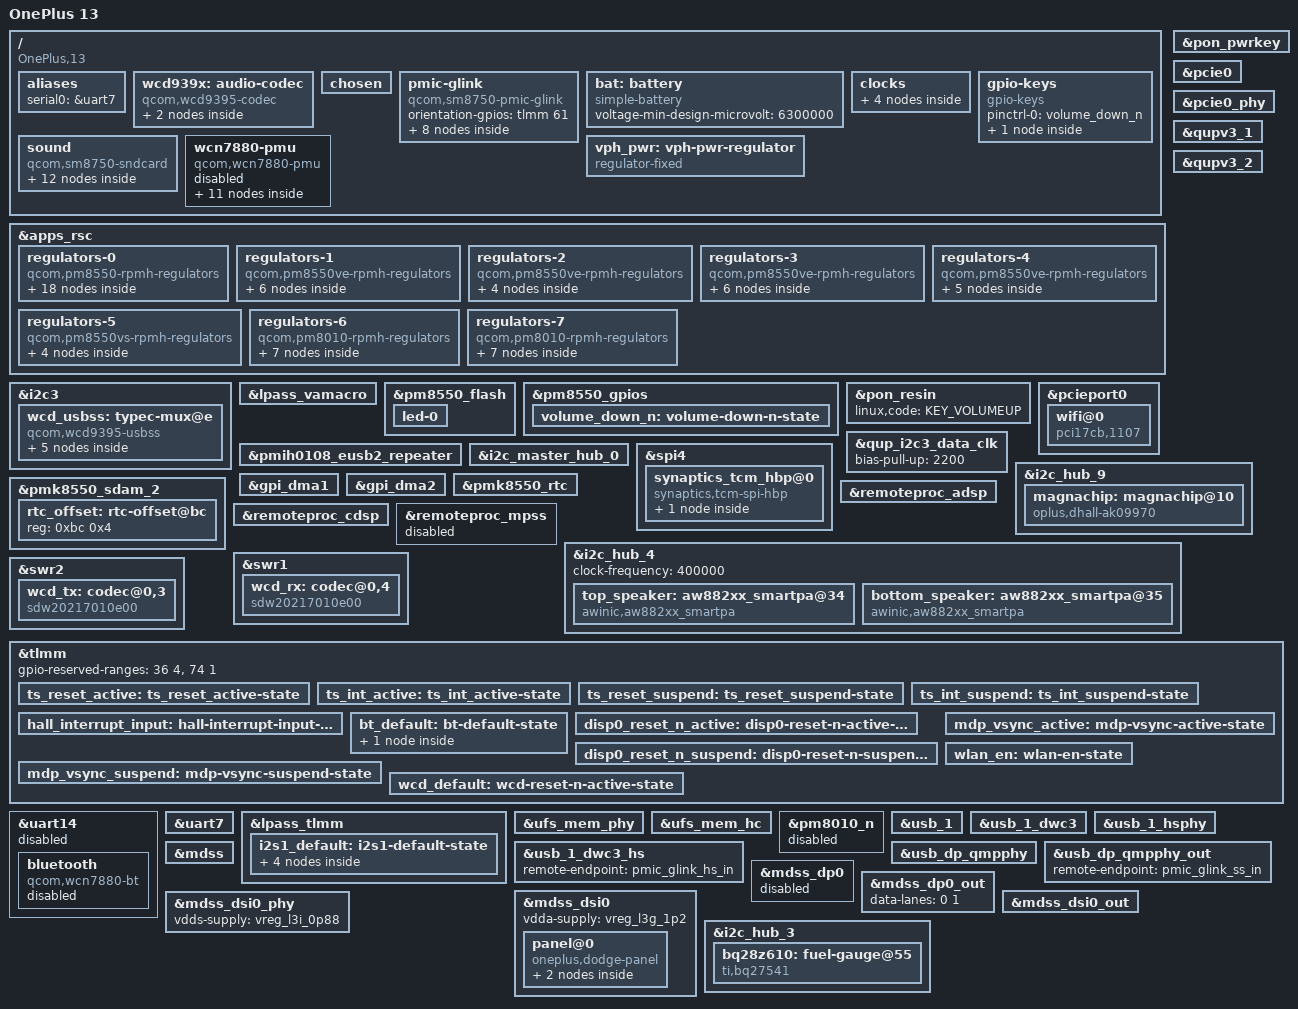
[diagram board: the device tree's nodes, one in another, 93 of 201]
// SPDX-License-Identifier: BSD-3-Clause
/*
 * Copyright (c) 2025 index986. All rights reserved.
 */

/dts-v1/;

#include <dt-bindings/gpio/gpio.h
#include <dt-bindings/leds/common.h>
#include <dt-bindings/regulator/qcom,rpmh-regulator.h>
#include "sm8750.dtsi"
#include "pm8010.dtsi"
#include "pm8550.dtsi"
#define PMK8550VE_SID 8
#include "pm8550ve.dtsi"
#include "pmd8028.dtsi"
#include "pmih0108.dtsi"
#include "pmk8550.dtsi"
#include "pmr735d_a.dtsi"
#include "sm8750-pmics.dtsi"

/ {
	model = "OnePlus 13";
	compatible = "OnePlus,13", "qcom,sm8750";
	chassis-type = "handset";

	aliases {
		serial0 = &uart7;
	};

	wcd939x: audio-codec {
		compatible = "qcom,wcd9395-codec", "qcom,wcd9390-codec";

		pinctrl-0 = <&wcd_default>;
		pinctrl-names = "default";

		qcom,micbias1-microvolt = <1800000>;
		qcom,micbias2-microvolt = <1800000>;
		qcom,micbias3-microvolt = <1800000>;
		qcom,micbias4-microvolt = <1800000>;
		qcom,mbhc-buttons-vthreshold-microvolt = <75000 150000 237000 500000 500000 500000 500000 500000>;
		qcom,mbhc-headset-vthreshold-microvolt = <1700000>;
		qcom,mbhc-headphone-vthreshold-microvolt = <50000>;
		qcom,rx-device = <&wcd_rx>;
		qcom,tx-device = <&wcd_tx>;

		reset-gpios = <&tlmm 101 GPIO_ACTIVE_LOW>;

		vdd-buck-supply = <&vreg_l15b_1p8>;
		vdd-rxtx-supply = <&vreg_l15b_1p8>;
		vdd-io-supply = <&vreg_l15b_1p8>;
		vdd-mic-bias-supply = <&vreg_bob1>;
		vdd-px-supply = <&vreg_l2i_1p2>;

		#sound-dai-cells = <1>;

		mode-switch;
		orientation-switch;

		port {
			wcd_codec_headset_in: endpoint {
				remote-endpoint = <&wcd_usbss_headset_out>;
			};
		};
	};

	chosen {
		#address-cells = <2>;
		#size-cells = <2>;
		ranges;
	};
	
	pmic-glink {
		compatible = "qcom,sm8750-pmic-glink",
			     "qcom,sm8550-pmic-glink",
			     "qcom,pmic-glink";
		#address-cells = <1>;
		#size-cells = <0>;
		orientation-gpios = <&tlmm 61 GPIO_ACTIVE_HIGH>;

		connector@0 {
			compatible = "usb-c-connector";
			reg = <0>;

			power-role = "dual";
			data-role = "dual";

			ports {
				#address-cells = <1>;
				#size-cells = <0>;

				port@0 {
					reg = <0>;
					pmic_glink_hs_in: endpoint {
						remote-endpoint = <&usb_1_dwc3_hs>;
					};
				};

				port@1 {
					reg = <1>;
					pmic_glink_ss_in: endpoint {
						remote-endpoint = <&usb_dp_qmpphy_out>;
					};
				};

				port@2 {
					reg = <2>;

					pmic_glink_sbu: endpoint {
						remote-endpoint = <&wcd_usbss_sbu_mux>;
					};
				};
			};
		};
	};

	bat: battery {
		compatible = "simple-battery";
		voltage-min-design-microvolt = <6300000>;
	};

	clocks {
		xo_board: xo-board {
			compatible = "fixed-clock";
			clock-frequency = <76800000>;
			#clock-cells = <0>;
		};

		sleep_clk: sleep-clk {
			compatible = "fixed-clock";
			clock-frequency = <32000>;
			#clock-cells = <0>;
		};

		bi_tcxo_div2: bi-tcxo-div2-clk {
			compatible = "fixed-factor-clock";
			#clock-cells = <0>;

			clocks = <&rpmhcc RPMH_CXO_CLK>;
			clock-mult = <1>;
			clock-div = <2>;
		};

		bi_tcxo_ao_div2: bi-tcxo-ao-div2-clk {
			compatible = "fixed-factor-clock";
			#clock-cells = <0>;

			clocks = <&rpmhcc RPMH_CXO_CLK_A>;
			clock-mult = <1>;
			clock-div = <2>;
		};
	};

	gpio-keys {
		compatible = "gpio-keys";

		pinctrl-0 = <&volume_down_n>;
		pinctrl-names = "default";

		key-volume-down {
			label = "Volume Down";
			linux,code = <KEY_VOLUMEDOWN>;
			gpios = <&pm8550_gpios 6 GPIO_ACTIVE_LOW>;
			debounce-interval = <15>;
			linux,can-disable;
			wakeup-source;
		};
	};

	sound {
		compatible = "qcom,sm8750-sndcard", "qcom,sm8450-sndcard";
		pinctrl-0 = <&i2s1_default>;
		pinctrl-names = "default";

		clocks = <&q6prmcc LPASS_CLK_ID_SEC_MI2S_IBIT LPASS_CLK_ATTRIBUTE_COUPLE_NO>;

		model = "astonsnd";
		audio-routing = "IN1_HPHL", "HPHL_OUT",
				"IN2_HPHR", "HPHR_OUT",
				"AMIC1", "MIC BIAS1",
				"AMIC2", "MIC BIAS2",
				"AMIC3", "MIC BIAS3",
				"AMIC4", "MIC BIAS4",
				"AMIC5", "MIC BIAS3",
				"TX SWR_INPUT0", "ADC1_OUTPUT",
				"TX SWR_INPUT1", "ADC2_OUTPUT",
				"TX SWR_INPUT0", "ADC3_OUTPUT",
				"TX SWR_INPUT1", "ADC4_OUTPUT";

		wcd-playback-dai-link {
			link-name = "WCD Playback";
			cpu {
				sound-dai = <&q6apmbedai RX_CODEC_DMA_RX_0>;
			};
			codec {
				sound-dai = <&wcd939x 0>, <&swr1 0>, <&lpass_rxmacro 0>;
			};
			platform {
				sound-dai = <&q6apm>;
			};
		};

		wcd-capture-dai-link {
			link-name = "WCD Capture";
			cpu {
				sound-dai = <&q6apmbedai TX_CODEC_DMA_TX_3>;
			};
			codec {
				sound-dai = <&wcd939x 1>, <&swr2 0>, <&lpass_txmacro 0>;
			};
			platform {
				sound-dai = <&q6apm>;
			};
		};

		secondary-i2s-dai-link {
			link-name = "Secondary MI2S Playback";

			cpu {
				sound-dai = <&q6apmbedai SECONDARY_MI2S_RX>;
			};

			platform {
				sound-dai = <&q6apm>;
			};

			codec {
				sound-dai = <&top_speaker>, <&bottom_speaker>;
			};
		};

	};
	
	vph_pwr: vph-pwr-regulator {
		compatible = "regulator-fixed";

		regulator-name = "vph_pwr";
		regulator-min-microvolt = <3700000>;
		regulator-max-microvolt = <3700000>;

		regulator-always-on;
		regulator-boot-on;
	};

	wcn7880-pmu { // No compatible drivers
		compatible = "qcom,wcn7880-pmu";

		pinctrl-names = "default";
		pinctrl-0 = <&wlan_en>, <&bt_default>;

		wlan-enable-gpios = <&tlmm 16 GPIO_ACTIVE_HIGH>;
		bt-enable-gpios = <&pm8550ve_f_gpios 3 GPIO_ACTIVE_HIGH>;

		vdd-supply = <&vreg_s5f_0p85>;
		vddio-supply = <&vreg_l3f_1p8>;
		vddio1p2-supply = <&vreg_l2f_1p2>;
		vddaon-supply = <&vreg_s4d_0p85>;
		vdddig-supply = <&vreg_s1d_0p97>;
		vddrfa1p2-supply = <&vreg_s7i_1p2>;
		vddrfa1p8-supply = <&vreg_s3g_1p8>;
			
		status = "disabled";

		clocks = <&rpmhcc RPMH_RF_CLK1>;

		regulators {
			vreg_pmu_rfa_cmn: ldo0 {
				regulator-name = "vreg_pmu_rfa_cmn";
			};

			vreg_pmu_aon_0p59: ldo1 {
				regulator-name = "vreg_pmu_aon_0p59";
			};

			vreg_pmu_wlcx_0p8: ldo2 {
				regulator-name = "vreg_pmu_wlcx_0p8";
			};

			vreg_pmu_wlmx_0p85: ldo3 {
				regulator-name = "vreg_pmu_wlmx_0p85";
			};

			vreg_pmu_btcmx_0p85: ldo4 {
				regulator-name = "vreg_pmu_btcmx_0p85";
			};

			vreg_pmu_rfa_0p8: ldo5 {
				regulator-name = "vreg_pmu_rfa_0p8";
			};

			vreg_pmu_rfa_1p2: ldo6 {
				regulator-name = "vreg_pmu_rfa_1p2";
			};

			vreg_pmu_rfa_1p8: ldo7 {
				regulator-name = "vreg_pmu_rfa_1p8";
			};

			vreg_pmu_pcie_0p9: ldo8 {
				regulator-name = "vreg_pmu_pcie_0p9";
			};

			vreg_pmu_pcie_1p8: ldo9 {
				regulator-name = "vreg_pmu_pcie_1p8";
			};
		};
	};
};

&apps_rsc {
	regulators-0 {
		compatible = "qcom,pm8550-rpmh-regulators";

		vdd-bob1-supply = <&vph_pwr>;
		vdd-bob2-supply = <&vph_pwr>;
		vdd-l1-l4-l10-supply = <&vreg_s3g_1p8>;
		vdd-l2-l13-l14-supply = <&vreg_bob1>;
		vdd-l3-supply = <&vreg_s7i_1p2>;
		vdd-l5-l16-supply = <&vreg_bob1>;
		vdd-l6-l7-supply = <&vreg_bob1>;
		vdd-l8-l9-supply = <&vreg_bob1>;
		vdd-l11-supply = <&vreg_s7i_1p2>;
		vdd-l12-supply = <&vreg_s3g_1p8>;
		vdd-l15-supply = <&vreg_s3g_1p8>;
		vdd-l17-supply = <&vreg_bob2>;

		qcom,pmic-id = "b";

		vreg_bob1: bob1 {
			regulator-name = "vreg_bob1";
			regulator-min-microvolt = <3008000>;
			regulator-max-microvolt = <4000000>;
			regulator-initial-mode = <RPMH_REGULATOR_MODE_HPM>;
		};

		vreg_bob2: bob2 {
			regulator-name = "vreg_bob2";
			regulator-min-microvolt = <2704000>;
			regulator-max-microvolt = <3008000>;
			regulator-initial-mode = <RPMH_REGULATOR_MODE_HPM>;
		};

		vreg_l1b_1p8: ldo1 {
			regulator-name = "vreg_l1b_1p8";
			regulator-min-microvolt = <1800000>;
			regulator-max-microvolt = <1800000>;
			regulator-initial-mode = <RPMH_REGULATOR_MODE_HPM>;
			regulator-allow-set-load;
			regulator-allowed-modes = <RPMH_REGULATOR_MODE_LPM
						   RPMH_REGULATOR_MODE_HPM>;
		};

		vreg_l2b_3p0: ldo2 {
			regulator-name = "vreg_l2b_3p0";
			regulator-min-microvolt = <3008000>;
			regulator-max-microvolt = <3048000>;
			regulator-initial-mode = <RPMH_REGULATOR_MODE_HPM>;
			regulator-allow-set-load;
			regulator-allowed-modes = <RPMH_REGULATOR_MODE_LPM
						   RPMH_REGULATOR_MODE_HPM>;
		};

		vreg_l4b_1p8: ldo4 {
			regulator-name = "vreg_l4b_1p8";
			regulator-min-microvolt = <1800000>;
			regulator-max-microvolt = <1800000>;
			regulator-initial-mode = <RPMH_REGULATOR_MODE_HPM>;
			regulator-allow-set-load;
			regulator-allowed-modes = <RPMH_REGULATOR_MODE_LPM
						   RPMH_REGULATOR_MODE_HPM>;
		};

		vreg_l5b_3p1: ldo5 {
			regulator-name = "vreg_l5b_3p1";
			regulator-min-microvolt = <3100000>;
			regulator-max-microvolt = <3148000>;
			regulator-initial-mode = <RPMH_REGULATOR_MODE_HPM>;
			regulator-allow-set-load;
			regulator-allowed-modes = <RPMH_REGULATOR_MODE_LPM
						   RPMH_REGULATOR_MODE_HPM>;
		};

		vreg_l6b_1p8: ldo6 {
			regulator-name = "vreg_l6b_1p8";
			regulator-min-microvolt = <1800000>;
			regulator-max-microvolt = <3008000>;
			regulator-initial-mode = <RPMH_REGULATOR_MODE_HPM>;
			regulator-allow-set-load;
			regulator-allowed-modes = <RPMH_REGULATOR_MODE_LPM
						   RPMH_REGULATOR_MODE_HPM>;
		};

		vreg_l7b_1p8: ldo7 {
			regulator-name = "vreg_l7b_1p8";
			regulator-min-microvolt = <1800000>;
			regulator-max-microvolt = <3008000>;
			regulator-initial-mode = <RPMH_REGULATOR_MODE_HPM>;
			regulator-allow-set-load;
			regulator-allowed-modes = <RPMH_REGULATOR_MODE_LPM
						   RPMH_REGULATOR_MODE_HPM>;

		};

		vreg_l8b_1p8: ldo8 {
			regulator-name = "vreg_l8b_1p8";
			regulator-min-microvolt = <1800000>;
			regulator-max-microvolt = <3008000>;
			regulator-initial-mode = <RPMH_REGULATOR_MODE_HPM>;
			regulator-allow-set-load;
			regulator-allowed-modes = <RPMH_REGULATOR_MODE_LPM
						   RPMH_REGULATOR_MODE_HPM>;
		};

		vreg_l9b_2p9: ldo9 {
			regulator-name = "vreg_l9b_2p9";
			regulator-min-microvolt = <2960000>;
			regulator-max-microvolt = <3008000>;
			regulator-initial-mode = <RPMH_REGULATOR_MODE_HPM>;
			regulator-allow-set-load;
			regulator-allowed-modes = <RPMH_REGULATOR_MODE_LPM
						   RPMH_REGULATOR_MODE_HPM>;
		};

		vreg_l10b_1p8: ldo10 {
			regulator-name = "vreg_l10b_1p8";
			regulator-min-microvolt = <1800000>;
			regulator-max-microvolt = <1800000>;
			regulator-initial-mode = <RPMH_REGULATOR_MODE_HPM>;
			regulator-allow-set-load;
			regulator-allowed-modes = <RPMH_REGULATOR_MODE_LPM
						   RPMH_REGULATOR_MODE_HPM>;
		};

		vreg_l11b_1p0: ldo11 {
			regulator-name = "vreg_l11b_1p0";
			regulator-min-microvolt = <1000000>;
			regulator-max-microvolt = <1100000>;
			regulator-initial-mode = <RPMH_REGULATOR_MODE_HPM>;
			regulator-allow-set-load;
			regulator-allowed-modes = <RPMH_REGULATOR_MODE_LPM
						   RPMH_REGULATOR_MODE_HPM>;
		};

		vreg_l12b_1p8: ldo12 {
			regulator-name = "vreg_l12b_1p8";
			regulator-min-microvolt = <1800000>;
			regulator-max-microvolt = <1800000>;
			regulator-initial-mode = <RPMH_REGULATOR_MODE_HPM>;
			regulator-allow-set-load;
			regulator-allowed-modes = <RPMH_REGULATOR_MODE_LPM
						   RPMH_REGULATOR_MODE_HPM>;
		};

		vreg_l13b_3p0: ldo13 {
			regulator-name = "vreg_l13b_3p0";
			regulator-min-microvolt = <3000000>;
			regulator-max-microvolt = <3000000>;
			regulator-initial-mode = <RPMH_REGULATOR_MODE_HPM>;
			regulator-allow-set-load;
			regulator-allowed-modes = <RPMH_REGULATOR_MODE_LPM
						   RPMH_REGULATOR_MODE_HPM>;
		};

		vreg_l14b_3p2: ldo14 {
			regulator-name = "vreg_l14b_3p2";
			regulator-min-microvolt = <3200000>;
			regulator-max-microvolt = <3200000>;
			regulator-initial-mode = <RPMH_REGULATOR_MODE_HPM>;
			regulator-allow-set-load;
			regulator-allowed-modes = <RPMH_REGULATOR_MODE_LPM
						   RPMH_REGULATOR_MODE_HPM>;
		};

		vreg_l15b_1p8: ldo15 {
			regulator-name = "vreg_l15b_1p8";
			regulator-min-microvolt = <1800000>;
			regulator-max-microvolt = <1800000>;
			regulator-initial-mode = <RPMH_REGULATOR_MODE_HPM>;
			regulator-always-on;
			regulator-allow-set-load;
			regulator-allowed-modes = <RPMH_REGULATOR_MODE_LPM
						   RPMH_REGULATOR_MODE_HPM>;
		};

		vreg_l16b_2p8: ldo16 {
			regulator-name = "vreg_l16b_2p8";
			regulator-min-microvolt = <2800000>;
			regulator-max-microvolt = <2800000>;
			regulator-initial-mode = <RPMH_REGULATOR_MODE_HPM>;
			regulator-allow-set-load;
			regulator-allowed-modes = <RPMH_REGULATOR_MODE_LPM
						   RPMH_REGULATOR_MODE_HPM>;
		};

		vreg_l17b_2p5: ldo17 {
			regulator-name = "vreg_l17b_2p5";
			regulator-min-microvolt = <2504000>;
			regulator-max-microvolt = <2504000>;
			regulator-initial-mode = <RPMH_REGULATOR_MODE_HPM>;
			regulator-allow-set-load;
			regulator-allowed-modes = <RPMH_REGULATOR_MODE_LPM
						   RPMH_REGULATOR_MODE_HPM>;
		};
	};

	regulators-1 {
		compatible = "qcom,pm8550ve-rpmh-regulators";

		vdd-l1-supply = <&vreg_s7i_1p2>;
		vdd-l2-supply = <&vreg_s1d_0p97>;
		vdd-l3-supply = <&vreg_s1d_0p97>;
		vdd-s1-supply = <&vph_pwr>;
		vdd-s3-supply = <&vph_pwr>;
		vdd-s4-supply = <&vph_pwr>;

		qcom,pmic-id = "d";

		vreg_s1d_0p97: smps1 {
			regulator-name = "vreg_s1d_0p97";
			regulator-min-microvolt = <880000>;
			regulator-max-microvolt = <1100000>;
			regulator-initial-mode = <RPMH_REGULATOR_MODE_HPM>;
		};

		vreg_s3d_1p2: smps3 {
			regulator-name = "vreg_s3d_1p2";
			regulator-min-microvolt = <1200000>;
			regulator-max-microvolt = <1300000>;
			regulator-initial-mode = <RPMH_REGULATOR_MODE_HPM>;
		};

		vreg_s4d_0p85: smps4 {
			regulator-name = "vreg_s4d_0p85";
			regulator-min-microvolt = <852000>;
			regulator-max-microvolt = <1036000>;
			regulator-initial-mode = <RPMH_REGULATOR_MODE_HPM>;
		};

		vreg_l1d_1p2: ldo1 {
			regulator-name = "vreg_l1d_1p2";
			regulator-min-microvolt = <1200000>;
			regulator-max-microvolt = <1200000>;
			regulator-initial-mode = <RPMH_REGULATOR_MODE_HPM>;
			regulator-allow-set-load;
			regulator-allowed-modes = <RPMH_REGULATOR_MODE_LPM
						   RPMH_REGULATOR_MODE_HPM>;
		};

		vreg_l2d_0p88: ldo2 {
			regulator-name = "vreg_l2d_0p88";
			regulator-min-microvolt = <880000>;
			regulator-max-microvolt = <912000>;
			regulator-initial-mode = <RPMH_REGULATOR_MODE_HPM>;
			regulator-allow-set-load;
			regulator-allowed-modes = <RPMH_REGULATOR_MODE_LPM
						   RPMH_REGULATOR_MODE_HPM>;
		};

		vreg_l3d_0p88: ldo3 {
			regulator-name = "vreg_l3d_0p88";
			regulator-min-microvolt = <880000>;
			regulator-max-microvolt = <920000>;
			regulator-initial-mode = <RPMH_REGULATOR_MODE_HPM>;
			regulator-allow-set-load;
			regulator-allowed-modes = <RPMH_REGULATOR_MODE_LPM
						   RPMH_REGULATOR_MODE_HPM>;
		};
	};

	regulators-2 {
		compatible = "qcom,pm8550ve-rpmh-regulators";

		vdd-l1-supply = <&vreg_s1d_0p97>;
		vdd-l2-supply = <&vreg_s7i_1p2>;
		vdd-l3-supply = <&vreg_s3g_1p8>;
		vdd-s5-supply = <&vph_pwr>;

		qcom,pmic-id = "f";

		vreg_s5f_0p85: smps5 {
			regulator-name = "vreg_s5f_0p85";
			regulator-min-microvolt = <852000>;
			regulator-max-microvolt = <1000000>;
			regulator-initial-mode = <RPMH_REGULATOR_MODE_HPM>;
		};

		vreg_l1f_0p88: ldo1 {
			regulator-name = "vreg_l1f_0p88";
			regulator-min-microvolt = <880000>;
			regulator-max-microvolt = <920000>;
			regulator-initial-mode = <RPMH_REGULATOR_MODE_HPM>;
			regulator-allow-set-load;
			regulator-allowed-modes = <RPMH_REGULATOR_MODE_LPM
						   RPMH_REGULATOR_MODE_HPM>;
		};

		vreg_l2f_1p2: ldo2 {
			regulator-name = "vreg_l2f_1p2";
			regulator-min-microvolt = <1200000>;
			regulator-max-microvolt = <1200000>;
			regulator-initial-mode = <RPMH_REGULATOR_MODE_HPM>;
			regulator-allow-set-load;
			regulator-allowed-modes = <RPMH_REGULATOR_MODE_LPM
						   RPMH_REGULATOR_MODE_HPM>;
		};

		vreg_l3f_1p8: ldo3 {
			regulator-name = "vreg_l3f_1p8";
			regulator-min-microvolt = <1800000>;
			regulator-max-microvolt = <1800000>;
			regulator-initial-mode = <RPMH_REGULATOR_MODE_HPM>;
			regulator-allow-set-load;
			regulator-allowed-modes = <RPMH_REGULATOR_MODE_LPM
						   RPMH_REGULATOR_MODE_HPM>;
		};

	};

	regulators-3 {
		compatible = "qcom,pm8550ve-rpmh-regulators";

		vdd-l1-supply = <&vreg_s1d_0p97>;
		vdd-l2-supply = <&vreg_s3g_1p8>;
		vdd-l3-supply = <&vreg_s7i_1p2>;
		vdd-s1-supply = <&vph_pwr>;
		vdd-s3-supply = <&vph_pwr>;

		qcom,pmic-id = "g";

		vreg_s1g_0p5: smps1 {
			regulator-name = "vreg_s1g_0p5";
			regulator-min-microvolt = <300000>;
			regulator-max-microvolt = <700000>;
			regulator-initial-mode = <RPMH_REGULATOR_MODE_HPM>;
		};

		vreg_s3g_1p8: smps3 {
			regulator-name = "vreg_s3g_1p8";
			regulator-min-microvolt = <1856000>;
			regulator-max-microvolt = <2000000>;
			regulator-initial-mode = <RPMH_REGULATOR_MODE_LPM>;
			regulator-allow-set-load;
			regulator-allowed-modes = <RPMH_REGULATOR_MODE_LPM
						   RPMH_REGULATOR_MODE_HPM>;
		};

		vreg_s4g_0p75: smps4 {
			regulator-name = "vreg_s4g_0p75";
			regulator-min-microvolt = <300000>;
			regulator-max-microvolt = <900000>;
			regulator-initial-mode = <RPMH_REGULATOR_MODE_HPM>;
		};

		vreg_l1g_0p91: ldo1 {
			regulator-name = "vreg_l1g_0p91";
			regulator-min-microvolt = <912000>;
			regulator-max-microvolt = <936000>;
			regulator-initial-mode = <RPMH_REGULATOR_MODE_HPM>;
			regulator-allow-set-load;
			regulator-allowed-modes = <RPMH_REGULATOR_MODE_LPM
						   RPMH_REGULATOR_MODE_HPM>;
		};

		vreg_l2g_1p8: ldo2 {
			regulator-name = "vreg_l2g_1p8";
			regulator-min-microvolt = <1200000>;
			regulator-max-microvolt = <1860000>;
			regulator-initial-mode = <RPMH_REGULATOR_MODE_HPM>;
			regulator-allow-set-load;
			regulator-allowed-modes = <RPMH_REGULATOR_MODE_LPM
						   RPMH_REGULATOR_MODE_HPM>;
		};

		vreg_l3g_1p2: ldo3 {
			regulator-name = "vreg_l3g_1p2";
			regulator-min-microvolt = <1200000>;
			regulator-max-microvolt = <1256000>;
			regulator-initial-mode = <RPMH_REGULATOR_MODE_HPM>;
			regulator-allow-set-load;
			regulator-allowed-modes = <RPMH_REGULATOR_MODE_LPM
						   RPMH_REGULATOR_MODE_HPM>;
		};
	};

	regulators-4 {
		compatible = "qcom,pm8550ve-rpmh-regulators";

		vdd-l1-supply = <&vreg_s7i_1p2>;
		vdd-l2-supply = <&vreg_s7i_1p2>;
		vdd-l3-supply = <&vreg_s1d_0p97>;
		vdd-s7-supply = <&vph_pwr>;
		vdd-s8-supply = <&vph_pwr>;

		qcom,pmic-id = "i";

		vreg_s7i_1p2: smps7 {
			regulator-name = "vreg_s7i_1p2";
			regulator-min-microvolt = <1224000>;
			regulator-max-microvolt = <1340000>;
			regulator-initial-mode = <RPMH_REGULATOR_MODE_HPM>;
		};

		vreg_s8i_0p9: smps8 {
			regulator-name = "vreg_s8i_0p9";
			regulator-min-microvolt = <900000>;
			regulator-max-microvolt = <972000>;
			regulator-initial-mode = <RPMH_REGULATOR_MODE_HPM>;
		};

		vreg_l1i_1p2: ldo1 {
			regulator-name = "vreg_l1i_1p2";
			regulator-min-microvolt = <1200000>;
			regulator-max-microvolt = <1200000>;
			regulator-initial-mode = <RPMH_REGULATOR_MODE_HPM>;
			regulator-allow-set-load;
			regulator-allowed-modes = <RPMH_REGULATOR_MODE_LPM
						   RPMH_REGULATOR_MODE_HPM>;
		};

		vreg_l2i_1p2: ldo2 {
			regulator-name = "vreg_l2i_1p2";
			regulator-min-microvolt = <1200000>;
			regulator-max-microvolt = <1200000>;
			regulator-initial-mode = <RPMH_REGULATOR_MODE_HPM>;
			regulator-allow-set-load;
			regulator-allowed-modes = <RPMH_REGULATOR_MODE_LPM
						   RPMH_REGULATOR_MODE_HPM>;
		};

		vreg_l3i_0p88: ldo3 {
			regulator-name = "vreg_l3i_0p88";
			regulator-min-microvolt = <880000>;
			regulator-max-microvolt = <912000>;
			regulator-initial-mode = <RPMH_REGULATOR_MODE_HPM>;
			regulator-allow-set-load;
			regulator-allowed-modes = <RPMH_REGULATOR_MODE_LPM
						   RPMH_REGULATOR_MODE_HPM>;
		};
	};

	regulators-5 {
		compatible = "qcom,pm8550vs-rpmh-regulators";

		vdd-l1-supply = <&vreg_s1d_0p97>;
		vdd-l2-supply = <&vreg_s7i_1p2>;
		vdd-s2-supply = <&vph_pwr>;
		vdd-s3-supply = <&vph_pwr>;
		vdd-s4-supply = <&vph_pwr>;

		qcom,pmic-id = "j";

		vreg_s2j_1p1: smps2 {
			regulator-name = "vreg_s2j_1p1";
			regulator-min-microvolt = <1000000>;
			regulator-max-microvolt = <1100000>;
			regulator-initial-mode = <RPMH_REGULATOR_MODE_HPM>;
		};

		vreg_s3j_1p1: smps3 {
			regulator-name = "vreg_s3j_1p1";
			regulator-min-microvolt = <1000000>;
			regulator-max-microvolt = <1100000>;
			regulator-initial-mode = <RPMH_REGULATOR_MODE_HPM>;
		};

		vreg_l1j_0p91: ldo1 {
			regulator-name = "vreg_l1j_0p91";
			regulator-min-microvolt = <880000>;
			regulator-max-microvolt = <920000>;
			regulator-initial-mode = <RPMH_REGULATOR_MODE_HPM>;
			regulator-allow-set-load;
			regulator-allowed-modes = <RPMH_REGULATOR_MODE_LPM
						   RPMH_REGULATOR_MODE_HPM>;
		};

		vreg_l2j_1p2: ldo2 {
			regulator-name = "vreg_l2j_1p2";
			regulator-min-microvolt = <1200000>;
			regulator-max-microvolt = <1200000>;
			regulator-initial-mode = <RPMH_REGULATOR_MODE_HPM>;
			regulator-allow-set-load;
			regulator-allowed-modes = <RPMH_REGULATOR_MODE_LPM
						   RPMH_REGULATOR_MODE_HPM>;
		};
	};

	regulators-6 {
		compatible = "qcom,pm8010-rpmh-regulators";
		qcom,pmic-id = "m";

		vdd-l1-l2-supply = <&vreg_s7i_1p2>;
		vdd-l3-l4-supply = <&vreg_bob2>;
		vdd-l5-supply = <&vreg_s3g_1p8>;
		vdd-l6-supply = <&vreg_bob1>;
		vdd-l7-supply = <&vreg_bob1>;

		vreg_l1m_1p1: ldo1 {
			regulator-name = "vreg_l1m_1p1";
			regulator-min-microvolt = <1104000>;
			regulator-max-microvolt = <1104000>;
			regulator-initial-mode = <RPMH_REGULATOR_MODE_HPM>;
			regulator-allow-set-load;
			regulator-allowed-modes = <RPMH_REGULATOR_MODE_LPM
						   RPMH_REGULATOR_MODE_HPM>;
		};

		vreg_l2m_1p056: ldo2 {
			regulator-name = "vreg_l2m_1p056";
			regulator-min-microvolt = <1056000>;
			regulator-max-microvolt = <1056000>;
			regulator-initial-mode = <RPMH_REGULATOR_MODE_HPM>;
			regulator-allow-set-load;
			regulator-allowed-modes = <RPMH_REGULATOR_MODE_LPM
						   RPMH_REGULATOR_MODE_HPM>;
		};

		vreg_l3m_2p8: ldo3 {
			regulator-name = "vreg_l3m_2p8";
			regulator-min-microvolt = <2800000>;
			regulator-max-microvolt = <2800000>;
			regulator-initial-mode = <RPMH_REGULATOR_MODE_HPM>;
		};

		vreg_l4m_2p8: ldo4 {
			regulator-name = "vreg_l4m_2p8";
			regulator-min-microvolt = <2800000>;
			regulator-max-microvolt = <2800000>;
			regulator-initial-mode = <RPMH_REGULATOR_MODE_HPM>;
		};

		vreg_l5m_1p8: ldo5 {
			regulator-name = "vreg_l5m_1p8";
			regulator-min-microvolt = <1800000>;
			regulator-max-microvolt = <1800000>;
			regulator-initial-mode = <RPMH_REGULATOR_MODE_HPM>;
		};

		vreg_l6m_2p8: ldo6 {
			regulator-name = "vreg_l6m_2p8";
			regulator-min-microvolt = <2800000>;
			regulator-max-microvolt = <2800000>;
			regulator-initial-mode = <RPMH_REGULATOR_MODE_HPM>;
		};

		vreg_l7m_2p96: ldo7 {
			regulator-name = "vreg_l7m_2p96";
			regulator-min-microvolt = <2960000>;
			regulator-max-microvolt = <2960000>;
			regulator-initial-mode = <RPMH_REGULATOR_MODE_HPM>;
		};
	};

	regulators-7 {
		compatible = "qcom,pm8010-rpmh-regulators";
		qcom,pmic-id = "n";

		vdd-l1-l2-supply = <&vreg_s7i_1p2>;
		vdd-l3-l4-supply = <&vreg_s3g_1p8>;
		vdd-l5-supply = <&vreg_bob2>;
		vdd-l6-supply = <&vreg_bob2>;
		vdd-l7-supply = <&vreg_bob1>;

		vreg_l1n_1p1: ldo1 {
			regulator-name = "vreg_l1n_1p1";
			regulator-min-microvolt = <1104000>;
			regulator-max-microvolt = <1104000>;
			regulator-initial-mode = <RPMH_REGULATOR_MODE_HPM>;
			regulator-allow-set-load;
			regulator-allowed-modes = <RPMH_REGULATOR_MODE_LPM
						   RPMH_REGULATOR_MODE_HPM>;
		};

		vreg_l2n_1p1: ldo2 {
			regulator-name = "vreg_l2n_1p1";
			regulator-min-microvolt = <1104000>;
			regulator-max-microvolt = <1104000>;
			regulator-initial-mode = <RPMH_REGULATOR_MODE_HPM>;
			regulator-allow-set-load;
			regulator-allowed-modes = <RPMH_REGULATOR_MODE_LPM
						   RPMH_REGULATOR_MODE_HPM>;
		};

		vreg_l3n_1p8: ldo3 {
			regulator-name = "vreg_l3n_1p8";
			regulator-min-microvolt = <1800000>;
			regulator-max-microvolt = <1800000>;
			regulator-initial-mode = <RPMH_REGULATOR_MODE_HPM>;
		};

		vreg_l4n_1p8: ldo4 {
			regulator-name = "vreg_l4n_1p8";
			regulator-min-microvolt = <1800000>;
			regulator-max-microvolt = <1800000>;
			regulator-initial-mode = <RPMH_REGULATOR_MODE_HPM>;
		};

		vreg_l5n_2p8: ldo5 {
			regulator-name = "vreg_l5n_2p8";
			regulator-min-microvolt = <2800000>;
			regulator-max-microvolt = <2800000>;
			regulator-initial-mode = <RPMH_REGULATOR_MODE_HPM>;
		};

		vreg_l6n_2p8: ldo6 {
			regulator-name = "vreg_l6n_2p8";
			regulator-min-microvolt = <2800000>;
			regulator-max-microvolt = <2800000>;
			regulator-initial-mode = <RPMH_REGULATOR_MODE_HPM>;
		};

		vreg_l7n_3p3: ldo7 {
			regulator-name = "vreg_l7n_3p3";
			regulator-min-microvolt = <3304000>;
			regulator-max-microvolt = <3304000>;
			regulator-initial-mode = <RPMH_REGULATOR_MODE_HPM>;
		};
	};
};

&i2c3 {
	status = "okay";

	wcd_usbss: typec-mux@e {
		compatible = "qcom,wcd9395-usbss", "qcom,wcd9390-usbss";
		reg = <0xe>;

		vdd-supply = <&vreg_l15b_1p8>;
		reset-gpios = <&tlmm 152 GPIO_ACTIVE_HIGH>;

		mode-switch;
		orientation-switch;

		ports {
			#address-cells = <1>;
			#size-cells = <0>;

			port@0 {
				reg = <0>;

				wcd_usbss_sbu_mux: endpoint {
					remote-endpoint = <&pmic_glink_sbu>;
				};
			};

			port@1 {
				reg = <1>;

				wcd_usbss_headset_out: endpoint {
					remote-endpoint = <&wcd_codec_headset_in>;
				};
			};
		};
	};
};

&lpass_vamacro {
	vdd-micb-supply = <&vreg_l1b_1p8>;
	qcom,dmic-sample-rate = <4800000>;
};

&pm8550_flash {
	status = "okay";
	led-0 {
		function = LED_FUNCTION_FLASH;
		color = <LED_COLOR_ID_WHITE>;
		led-sources = <1>, <4>;
		led-max-microamp = <500000>;
		flash-max-microamp = <2000000>;
		flash-max-timeout-us = <1280000>;
		function-enumerator = <0>;
	};
};


&pm8550_gpios {
	volume_down_n: volume-down-n-state {
		pins = "gpio6";
		function = "normal";
		bias-pull-up;
		input-enable;
		power-source = <1>;
	};
};

&pon_pwrkey {
	status = "okay";
};

&pon_resin {
	linux,code = <KEY_VOLUMEUP>;

	status = "okay";
};

&pcie0 {
	wake-gpios = <&tlmm 104 GPIO_ACTIVE_HIGH>;
	perst-gpios = <&tlmm 102 GPIO_ACTIVE_LOW>;

	pinctrl-0 = <&pcie0_default_state>;
	pinctrl-names = "default";

	status = "okay";
};

&pcie0_phy {
	vdda-phy-supply = <&vreg_l1f_0p88>;
	vdda-pll-supply = <&vreg_l3g_1p2>;

	status = "okay";
};

&pcieport0 {
	wifi@0 {
		compatible = "pci17cb,1107";
		reg = <0x10000 0x0 0x0 0x0 0x0>;

		vddrfacmn-supply = <&vreg_pmu_rfa_cmn>;
		vddaon-supply = <&vreg_pmu_aon_0p59>;
		vddwlcx-supply = <&vreg_pmu_wlcx_0p8>;
		vddwlmx-supply = <&vreg_pmu_wlmx_0p85>;
		vddrfa0p8-supply = <&vreg_pmu_rfa_0p8>;
		vddrfa1p2-supply = <&vreg_pmu_rfa_1p2>;
		vddrfa1p8-supply = <&vreg_pmu_rfa_1p8>;
		vddpcie0p9-supply = <&vreg_pmu_pcie_0p9>;
		vddpcie1p8-supply = <&vreg_pmu_pcie_1p8>;
	};
};

&pmih0108_eusb2_repeater {
	status = "okay";

	vdd18-supply = <&vreg_l15b_1p8>;
	vdd3-supply = <&vreg_l5b_3p1>;
};

&qup_i2c3_data_clk {
	/* Use internal I2C pull-up */
	bias-pull-up = <2200>;
};

&qupv3_1 {
	status = "okay";
};

&qupv3_2 {
	status = "okay";
};

&i2c_master_hub_0 {
	status = "okay";
};

&i2c_hub_9 {
	status = "okay";
	magnachip: magnachip@10 {
		compatible = "oplus,dhall-ak09970";
		reg = <0x10>;
		vcc-supply = <&vreg_l1b_1p8>;
		interrupt-parent = <&tlmm>;
		interrupts = <17 2>;
		threeaxis_hall_support;
		dhall,irq-gpio = <&tlmm 17 0x2008>;
		pinctrl-names = "hall_interrupt_input";
		pinctrl-0 = <&hall_interrupt_input>;
	};
};

&spi4 {
	status = "okay";
	synaptics_tcm_hbp@0 {
		compatible = "synaptics,tcm-spi-hbp";
		reg = <0>;
		chip-name = "S3910";
		spi-max-frequency = <19000000>;
		interrupt-parent = <&tlmm>;
		interrupts = <162 0x2008>;
		vdd-supply = <&vreg_l4b_1p8>;
		synaptics,irq-gpio   = <&tlmm 162 0x2008>;
		synaptics,reset-gpio = <&tlmm 161 GPIO_ACTIVE_LOW>;
		synaptics,avdd-gpio  = <&pm8550vs_j_gpios 3 GPIO_ACTIVE_LOW>;
		pinctrl-names = "ts_spi_active", "ts_spi_suspend";
		pinctrl-0 = <&ts_int_active &ts_reset_active>;
		pinctrl-1 = <&ts_int_suspend &ts_reset_suspend>;
		panel_type = <10 3 3 3>;
		firmware_name = "AA545";
		touchpanel,panel-coords = <20224 44480>;
		touchpanel,tx-rx-num = <17 38>;
		touchpanel,tp_ic_type = <2>;

		S3910_PANEL7 {
			touchpanel,tx-rx-num = <18 40>;
		};
	};
};


&gpi_dma1 {
	status = "okay";
};

&gpi_dma2 {
	status = "okay";
};

&pmk8550_rtc {
	nvmem-cells = <&rtc_offset>;
	nvmem-cell-names = "offset";
};

&pmk8550_sdam_2 {
	rtc_offset: rtc-offset@bc {
		reg = <0xbc 0x4>;
	};
};

&remoteproc_adsp {
	firmware-name = "qcom/sm8750/OnePlus/adsp.mbn",
			"qcom/sm8750/OnePlus/adsp_dtb.mbn";

	status = "okay";
};

&remoteproc_cdsp {
	firmware-name = "qcom/sm8750/OnePlus/cdsp.mbn",
			"qcom/sm8750/OnePlus/cdsp_dtb.mbn";

	status = "okay";
};

&remoteproc_mpss {
	firmware-name = "qcom/sm8750/OnePlus/modem.mbn",
			"qcom/sm8750/OnePlus/modem_dtb.mbn";

	status = "fail";
};

&i2c_hub_4 {
	status = "okay";
	clock-frequency = <400000>;

	top_speaker: aw882xx_smartpa@34 {
		compatible = "awinic,aw882xx_smartpa";
		reg = <0x34>;
		reset-gpio = <&tlmm 2 GPIO_ACTIVE_HIGH>;
		sync-load = <1>;
		sound-channel = <0>;
		aw-re-min = <5300>;
		aw-re-max = <7500>;
		aw-re-default = <5800>;
		aw-f0-min = <100>;
		aw-f0-max = <2000>;
		aw-f0-default = <758>;
		monitor-mode = "hal_monitor";
		f0-enable = <1>;
		status = "okay";

		#sound-dai-cells = <0>;
	};

	bottom_speaker: aw882xx_smartpa@35 {
		compatible = "awinic,aw882xx_smartpa";
		reg = <0x35>;
		reset-gpio = <&tlmm 164 GPIO_ACTIVE_HIGH>;
		sync-load = <1>;
		sound-channel = <1>;
		aw-re-min = <5300>;
		aw-re-max = <7500>;
		aw-re-default = <6100>;
		aw-f0-min = <100>;
		aw-f0-max = <2000>;
		aw-f0-default = <714>;
		monitor-mode = "hal_monitor";
		f0-enable = <1>;
		status = "okay";

		#sound-dai-cells = <0>;
	};
};

&swr1 {
	status = "okay";

	/* WCD9395 RX */
	wcd_rx: codec@0,4 {
		compatible = "sdw20217010e00";
		reg = <0 4>;

		/*
		 * WCD9395 RX Port 1 (HPH_L/R)      <=> SWR1 Port 1 (HPH_L/R)
		 * WCD9395 RX Port 2 (CLSH)         <=> SWR1 Port 2 (CLSH)
		 * WCD9395 RX Port 3 (COMP_L/R)     <=> SWR1 Port 3 (COMP_L/R)
		 * WCD9395 RX Port 4 (LO)           <=> SWR1 Port 4 (LO)
		 * WCD9395 RX Port 5 (DSD_L/R)      <=> SWR1 Port 5 (DSD_L/R)
		 * WCD9395 RX Port 6 (HIFI_PCM_L/R) <=> SWR1 Port 9 (HIFI_PCM_L/R)
		 */
		qcom,rx-port-mapping = <1 2 3 10>;
	};
};

&swr2 {
	status = "okay";

	/* WCD9395 TX */
	wcd_tx: codec@0,3 {
		compatible = "sdw20217010e00";
		reg = <0 3>;

		/*
		 * WCD9395 TX Port 1 (ADC1,2,3,4)         <=> SWR2 Port 2 (TX SWR_INPUT 0,1,2,3)
		 * WCD9395 TX Port 2 (ADC3,4 & DMIC0,1)   <=> SWR2 Port 2 (TX SWR_INPUT 0,1,2,3)
		 * WCD9395 TX Port 3 (DMIC0,1,2,3 & MBHC) <=> SWR2 Port 3 (TX SWR_INPUT 4,5,6,7)
		 * WCD9395 TX Port 4 (DMIC4,5,6,7)        <=> SWR2 Port 4 (TX SWR_INPUT 8,9,10,11)
		 */
		qcom,tx-port-mapping = <4 5 6 11>;
	};
};

&tlmm {
	/* reserved for secure world */
	gpio-reserved-ranges = <36 4>, <74 1>;

	ts_reset_active: ts_reset_active-state {
		pins = "gpio161";
		function = "gpio";
		bias-disable;
		output-low;
		drive-strength = <8>;
	};

	ts_int_active: ts_int_active-state {
		pins = "gpio162";
		function = "gpio";
		bias-pull-up;
		drive-strength = <8>;
		input-enable;
	};

	ts_reset_suspend: ts_reset_suspend-state {
		pins = "gpio161";
		function = "gpio";
		bias-pull-down;
		drive-strength = <2>;
	};

	ts_int_suspend: ts_int_suspend-state {
		pins = "gpio162";
		function = "gpio";
		bias-pull-down;
		drive-strength = <2>;
	};
	
	hall_interrupt_input: hall-interrupt-input-state {
		pins = "gpio97";
		function = "gpio";
		drive-strength = <2>;
		bias-pull-up;
	};

	bt_default: bt-default-state {
		sw-ctrl-pins {
			pins = "gpio18";
			function = "gpio";
			bias-pull-down;
		};
	};

	disp0_reset_n_active: disp0-reset-n-active-state {
		pins = "gpio98";
		function = "gpio";
		drive-strength = <8>;
		bias-disable;
	};

	disp0_reset_n_suspend: disp0-reset-n-suspend-state {
		pins = "gpio98";
		function = "gpio";
		drive-strength = <2>;
		bias-pull-down;
	};

	mdp_vsync_active: mdp-vsync-active-state {
		pins = "gpio86";
		function = "mdp_vsync";
		drive-strength = <2>;
		bias-pull-down;
	};

	mdp_vsync_suspend: mdp-vsync-suspend-state {
		pins = "gpio86";
		function = "mdp_vsync";
		drive-strength = <2>;
		bias-pull-down;
	};

	wlan_en: wlan-en-state {
		pins = "gpio16";
		function = "gpio";
		drive-strength = <8>;
		bias-pull-down;
	};
	
	wcd_default: wcd-reset-n-active-state {
		pins = "gpio101";
		function = "gpio";
		drive-strength = <16>;
		bias-disable;
		output-low;
	};
};

&uart14 {
	status = "disabled";

	bluetooth {
		compatible = "qcom,wcn7880-bt";

		vddrfacmn-supply = <&vreg_pmu_rfa_cmn>;
		vddaon-supply = <&vreg_pmu_aon_0p59>;
		vddwlcx-supply = <&vreg_pmu_wlcx_0p8>;
		vddwlmx-supply = <&vreg_pmu_wlmx_0p85>;
		vddrfa0p8-supply = <&vreg_pmu_rfa_0p8>;
		vddrfa1p2-supply = <&vreg_pmu_rfa_1p2>;
		vddrfa1p8-supply = <&vreg_pmu_rfa_1p8>;

		max-speed = <3200000>;
		status = "disabled";
	};
};

&uart7 {
	status = "okay";
};

/* Pinctrl */
&lpass_tlmm {
	i2s1_default: i2s1-default-state {
		sck-pins {
			pins = "gpio6";
			function = "i2s1_clk";
			drive-strength = <8>;
			bias-disable;
			output-high;
		};
		ws-pins {
			pins = "gpio7";
			// Correct function name from the driver source
			function = "i2s1_ws";
			drive-strength = <8>;
			bias-disable;
			output-high;
		};
		data0-pins {
			pins = "gpio8";
			// Correct function name from the driver source
			function = "i2s1_data";
			drive-strength = <8>;
			bias-disable;
			output-high;
		};
		data1-pins {
			pins = "gpio9";
			// Correct function name from the driver source
			function = "i2s1_data";
			drive-strength = <8>;
			bias-disable;
			output-high;
		};
	};
};

&ufs_mem_phy {
	vdda-phy-supply = <&vreg_l1j_0p91>;
	vdda-pll-supply = <&vreg_l3g_1p2>;

	status = "okay";
};

&ufs_mem_hc {
	reset-gpios = <&tlmm 215 GPIO_ACTIVE_LOW>;

	vcc-supply = <&vreg_l17b_2p5>;
	vcc-max-microamp = <1300000>;
	vccq-supply = <&vreg_l1d_1p2>;
	vccq-max-microamp = <1200000>;

	status = "okay";
};

&pm8010_n {
  status = "disabled";
};

&usb_1 {
	status = "okay";
};

&usb_1_dwc3 {
	dr_mode = "otg";
	usb-role-switch;
};

&usb_1_dwc3_hs {
	remote-endpoint = <&pmic_glink_hs_in>;
};

&usb_1_hsphy {
	vdd-supply = <&vreg_l2d_0p88>;
	vdda12-supply = <&vreg_l3g_1p2>;

	phys = <&pmih0108_eusb2_repeater>;

	status = "okay";
};

&usb_dp_qmpphy {
	vdda-phy-supply = <&vreg_l3g_1p2>;
	vdda-pll-supply = <&vreg_l2d_0p88>;

	status = "okay";
};

&usb_dp_qmpphy_out {
	remote-endpoint = <&pmic_glink_ss_in>;
};

&mdss {
	status = "okay";
};

// Disabled for now until upstream DP merged
&mdss_dp0 {
	status = "disabled";
};

&mdss_dp0_out {
	data-lanes = <0 1>;
};

&mdss_dsi0 {
	vdda-supply = <&vreg_l3g_1p2>;

	status = "okay";

	panel@0 {
		compatible = "oneplus,dodge-panel";
		reg = <0>;

		pinctrl-names = "default", "sleep";
		pinctrl-0 = <&disp0_reset_n_active>, <&mdp_vsync_active>;
		pinctrl-1 = <&disp0_reset_n_suspend>, <&mdp_vsync_suspend>;

		vddio-supply = <&vreg_l12b_1p8>;
		vci-supply = <&vreg_l13b_3p0>;
		vdd-supply = <&vreg_l11b_1p0>;

		reset-gpios = <&tlmm 98 GPIO_ACTIVE_LOW>;

		port {
			panel0_in: endpoint {
				remote-endpoint = <&mdss_dsi0_out>;
			};
		};
	};
};

&mdss_dsi0_out {
	remote-endpoint = <&panel0_in>;
	data-lanes = <0 1 2 3>;
};

&mdss_dsi0_phy {
	vdds-supply = <&vreg_l3i_0p88>;

	status = "okay";
};

&i2c_hub_3 {
    status = "okay";
    bq28z610: fuel-gauge@55 {
        compatible = "ti,bq27541";
        reg = <0x55>;
        monitored-battery = <&bat>;
    };
};
